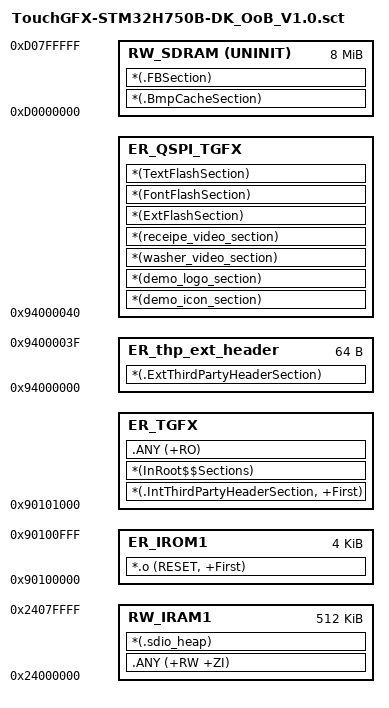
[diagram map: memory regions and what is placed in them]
; *************************************************************
; *** Scatter-Loading Description File generated by uVision ***
; *************************************************************

LR_IROM1 0x90100000 0x1000  {    ; load region size_region
	ER_IROM1 0x90100000 0x1000 {
		*.o (RESET, +First)
}
}
LR_TGFX 0x90101000   {    ; load region size_region
	ER_TGFX 0x90101000  {
		*(.IntThirdPartyHeaderSection, +First)
		*(InRoot$$Sections)
		 .ANY (+RO)    
}
	RW_IRAM1 0x24000000 0x80000  {  ; RW data
		.ANY (+RW +ZI)
		*(.sdio_heap)
}
	RW_SDRAM 0xD0000000 UNINIT  0x800000  {  ; RW data
		*(.BmpCacheSection)
		*(.FBSection)
}
}
LR_QSPI_TGFX 0x94000000 0x4000000  {    ; load region size_region
	ER_thp_ext_header 0x94000000 0x40  {	
		*(.ExtThirdPartyHeaderSection)
}
	ER_QSPI_TGFX 0x94000040   { 
		*(demo_icon_section)
		*(demo_logo_section)
		*(washer_video_section)
		*(receipe_video_section)
		*(ExtFlashSection)
		*(FontFlashSection)
		*(TextFlashSection)
}
}

